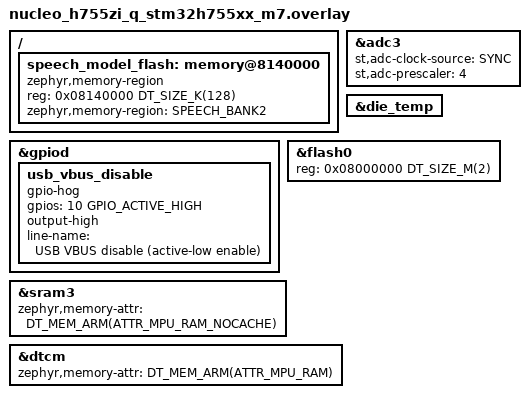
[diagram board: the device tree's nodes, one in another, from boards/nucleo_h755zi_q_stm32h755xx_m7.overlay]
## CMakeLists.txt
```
cmake_minimum_required(VERSION 3.20.0)

set(extra_conf_file "")
set(extra_dtc_overlay_file "")
set(board_compile_definitions "")

if(BOARD STREQUAL "nucleo_h755zi_q/stm32h755xx/m7")
  set(extra_conf_file "${CMAKE_CURRENT_SOURCE_DIR}/boards/nucleo_h755zi_q_stm32h755xx_m7.conf")
  set(extra_dtc_overlay_file "${CMAKE_CURRENT_SOURCE_DIR}/boards/nucleo_h755zi_q_stm32h755xx_m7.overlay")
  set(board_sources
    src/boot_optimizations.c
    src/board_io.c
    src/board_temperature_nucleo.c
    src/usb_host/stm32_hcd_adapter.c
    src/usb_host/usb_gpio_capture.c
    src/usb_host/usb_host_shell.c
    src/usb_host/usb_boot_mouse_class.c
    src/usb_host/usb_audio_capture.c
    src/usb_host/usb_audio_buffer.c
    src/usb_host/usb_audio_desc.c
    src/usb_host/usb_class_select.c
    third_party/stm32-mw-usb-host/Core/Src/usbh_core.c
    third_party/stm32-mw-usb-host/Core/Src/usbh_ctlreq.c
    third_party/stm32-mw-usb-host/Core/Src/usbh_ioreq.c
    third_party/stm32-mw-usb-host/Core/Src/usbh_pipes.c
  )
  set(board_include_dirs
    third_party/stm32-mw-usb-host/Core/Inc
  )
elseif(BOARD STREQUAL "native_sim/native/64")
  set(board_sources
    src/board_io_native_sim.c
    src/board_temperature_native_sim.c
    src/usb_host/usb_host_native_sim.c
  )
  set(board_compile_definitions APP_SIMULATED_HW)
elseif(BOARD STREQUAL "mps2/an500")
  set(extra_conf_file "${CMAKE_CURRENT_SOURCE_DIR}/boards/mps2_an500.conf")
  set(extra_dtc_overlay_file "${CMAKE_CURRENT_SOURCE_DIR}/boards/mps2_an500.overlay")
  set(board_sources
    src/board_io_native_sim.c
    src/board_temperature_native_sim.c
    src/usb_host/usb_host_native_sim.c
  )
  set(board_compile_definitions APP_SIMULATED_HW)
else()
  message(FATAL_ERROR "Unsupported BOARD target: ${BOARD}")
endif()

if(extra_conf_file)
  set(CONF_FILE "${CMAKE_CURRENT_SOURCE_DIR}/prj.conf;${extra_conf_file}" CACHE STRING "" FORCE)
endif()

if(extra_dtc_overlay_file)
  set(DTC_OVERLAY_FILE "${extra_dtc_overlay_file}" CACHE STRING "" FORCE)
endif()

set(SPEECH_TFLM_DIR "${CMAKE_CURRENT_SOURCE_DIR}/third_party/tflite-micro")
if(BOARD STREQUAL "nucleo_h755zi_q/stm32h755xx/m7")
  list(APPEND ZEPHYR_EXTRA_MODULES "${SPEECH_TFLM_DIR}")
endif()
find_package(Zephyr REQUIRED HINTS $ENV{ZEPHYR_BASE})
project(zephyr_hello_shell)

if(CONFIG_APP_USB_HOST_EVENT_WORKER)
  target_sources(app PRIVATE src/usb_host/usb_host_events.c)
endif()

if(CONFIG_APP_SPEECH_AI)
  include(cmake/speech_model.cmake)
  target_sources(app PRIVATE src/speech/speech_audio.c src/speech/speech_decision.c)
endif()
if(BOARD STREQUAL "nucleo_h755zi_q/stm32h755xx/m7")
  include(cmake/patch_stm32_hcd.cmake)
endif()

if(DEFINED ENV{SOURCE_DATE_EPOCH} AND
   NOT "$ENV{SOURCE_DATE_EPOCH}" MATCHES "^[0-9]+$")
  message(FATAL_ERROR "SOURCE_DATE_EPOCH must be a nonnegative integer")
endif()

string(TIMESTAMP APP_BUILD_TIMESTAMP "%Y-%m-%dT%H:%M:%SZ" UTC)
target_compile_definitions(app PRIVATE
  APP_BUILD_TIMESTAMP=\"${APP_BUILD_TIMESTAMP}\"
  ${board_compile_definitions}
)

target_sources(app PRIVATE
  src/main.c
  src/http_server.c
  src/web_assets.c
  src/mjpeg_multipart.c
  src/camera_frames.c
  src/camera_stream.c
  src/audio_wire.c
  src/audio_stream.c
  src/speech/speech_service.c
  src/speech/speech_attempt.c
  src/speech/speech_json.c
  src/usb_host/usb_boot_mouse_report.c
  ${board_sources}
)

target_include_directories(app PRIVATE
  src/usb_host
  src/speech
  ${board_include_dirs}
)

zephyr_linker_sources(SECTIONS sections-rom.ld)
zephyr_linker_section(NAME http_resource_desc_board_http_service
                      KVMA RAM_REGION GROUP RODATA_REGION)
```

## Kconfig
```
source "Kconfig.zephyr"

config APP_SPEECH_AI
	bool "On-board English keyword recognition"
	depends on APP_USB_HOST_HCD
	select CPP
	select TENSORFLOW_LITE_MICRO

config APP_HTTP_PORT
	int "Application HTTP server port"
	range 1 65535
	default 80
	help
	  TCP port used by the application dashboard and API.

config APP_USB_HOST_HCD
	bool "Enable STM32 USB host controller (HCD) support"
	default n
	select USE_STM32_HAL_HCD
	select USE_STM32_LL_USB
	select USE_STM32_HAL_PWR_EX
	help
	  Enables the STM32Cube HAL Host Controller Driver (HCD) module,
	  used by the STM32 USB Host Core bridge to drive OTG_FS in host
	  mode for USB device enumeration.

config APP_USB_HOST_EVENT_WORKER
	bool "Experimental FIFO-notification-driven USB host worker"
	depends on APP_USB_HOST_HCD
	default y
	select THREAD_RUNTIME_STATS
	help
	  Wake the USB host worker on queued HAL notifications and SOF ticks
	  instead of continuously busy-waiting in HOST_CLASS. Hardware IRQ
	  handling and microphone resubmission remain in interrupt context.
	  Disable for the original 50 us polling baseline.

config APP_USB_HOST_NO_IDLE_SLEEP
	bool "Diagnostic: skip CPU WFI/WFE while testing USB"
	depends on APP_USB_HOST_HCD
	select ARM_ON_ENTER_CPU_IDLE_HOOK
	default n
	help
	  Diagnostic comparison only. Keep the event worker blocking, but
	  prevent the idle thread from sleeping the CPU. This does not save
	  CPU power and must not be mistaken for a production fix.

config APP_USB_HOST_ULPI_SLEEP_CLOCK_FIX
	bool "Disable unused USB2 ULPI sleep clock for embedded FS PHY"
	depends on APP_USB_HOST_HCD
	default y
	help
	  Match Zephyr's STM32 USB device drivers: USB2's embedded FS PHY
	  needs the unused ULPI clock disabled in CPU sleep. Disable only
	  to reproduce the historical USB timing failure.

config APP_MPU_PROTECTION_TEST
	bool "Enable the test-only LED MPU cross-access probe"
	depends on USERSPACE
	default n
```

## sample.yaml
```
sample:
  description: External Hello World app with Zephyr serial shell and HTTP board I/O server
  name: zephyr hello shell
tests:
  app.zephyr_hello_shell:
    tags:
      - introduction
      - shell
    platform_allow:
      - nucleo_h755zi_q/stm32h755xx/m7
    harness: shell
    filter: CONFIG_SERIAL and dt_chosen_enabled("zephyr,shell-uart")
    harness_config:
      shell_commands:
        - command: "help"
          expected: "Available commands:"
        - command: "kernel version"
          expected: "Zephyr version .*"
        - command: "leds on green"
          expected: "green -> on"
        - command: "leds status green"
          expected: "green: on"
        - command: "leds off all"
          expected: "red -> off"
```

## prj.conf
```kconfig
CONFIG_MAIN_STACK_SIZE=3072
CONFIG_SYSTEM_WORKQUEUE_STACK_SIZE=1024

CONFIG_SERIAL=y
CONFIG_CONSOLE=y
CONFIG_UART_CONSOLE=y
CONFIG_GPIO=y
CONFIG_SHELL=y
CONFIG_SHELL_BACKEND_SERIAL=y
CONFIG_BOOT_BANNER=n
CONFIG_LOG=y
CONFIG_LOG_DEFAULT_LEVEL=2
CONFIG_LOG_CMDS=y
CONFIG_LOG_RUNTIME_FILTERING=y
CONFIG_LOG_RUNTIME_DEFAULT_LEVEL=2
CONFIG_LOG_BACKEND_UART=n
CONFIG_SHELL_LOG_BACKEND=y
CONFIG_SHELL_BACKEND_SERIAL_LOG_LEVEL_WRN=y
CONFIG_SHELL_THREAD_PRIORITY_OVERRIDE=y
CONFIG_SHELL_THREAD_PRIORITY=9
CONFIG_KERNEL_SHELL=y
CONFIG_THREAD_RUNTIME_STATS=y
CONFIG_JSON_LIBRARY=y

CONFIG_NETWORKING=y
CONFIG_NET_L2_ETHERNET=y
CONFIG_NET_IPV4=y
CONFIG_NET_TCP=y
CONFIG_NET_ARP=y
CONFIG_NET_CONFIG_SETTINGS=y
CONFIG_NET_CONFIG_NEED_IPV4=y
CONFIG_NET_CONFIG_MY_IPV4_ADDR="192.168.55.2"
CONFIG_NET_CONFIG_MY_IPV4_NETMASK="255.255.255.0"
CONFIG_NET_CONFIG_PEER_IPV4_ADDR="192.168.55.100"
# Don't block boot (main) waiting for PHY autonegotiation; the static
# address is still assigned immediately and the link comes up in background.
CONFIG_NET_CONFIG_INIT_TIMEOUT=0
CONFIG_NET_TCP_TIME_WAIT_DELAY=0
CONFIG_NET_SHELL=y
# The camera stream sends to one client at a time on a blocking socket.
# If a client disconnects uncleanly (no FIN/RST reaches the board, e.g.
# TCP window closes because the client just stops reading), a plain
# blocking send() can wait forever, wedging the single stream thread
# and holding onto its buffered/in-flight frame data indefinitely. That
# starves the shared network buffer pool the port-80 dashboard thread
# also needs. Enable per-socket send/receive timeouts so camera_stream.c
# can bound how long it waits on a stuck client and recover.
CONFIG_NET_CONTEXT_SNDTIMEO=y
CONFIG_NET_CONTEXT_RCVTIMEO=y
# Zephyr's global file-descriptor table (ZVFS_OPEN_MAX) defaults to only
# 4 slots, shared by every socket in the whole system. The dashboard
# alone already needs 4 (1 listener + CONFIG_HTTP_SERVER_MAX_CLIENTS=3),
# so the camera stream's 2 additional sockets (1 listener + 1 serving
# client) exhausted the pool and silently starved the dashboard of a
# free fd to accept new connections on. Size both the fd table and the
# poll() entry table generously for dashboard, camera and microphone:
# three listeners, three dashboard clients, camera client, mic client and
# one transient busy-response client, with teardown/headroom.
CONFIG_ZVFS_OPEN_MAX=20
CONFIG_ZVFS_POLL_MAX=12
CONFIG_NET_MAX_CONTEXTS=16
CONFIG_NET_MAX_CONN=16
CONFIG_SHELL_STACK_SIZE=3072
# TCP keeps unacknowledged data in a per-connection send queue built from
# TX DATA net_bufs, and each transmitted segment is a second copy from the
# same pool. The default pool (36 x 128 B) with its derived send window
# (pool/3 = 1536 B) deadlocks when camera (8081) and microphone (8082)
# stream together: both send queues pin ~25 buffers and the 11 left cannot
# hold one MSS segment, so neither connection can ever transmit again.
# Pin the per-connection window (2 x MSS) and size the pool for camera,
# microphone and dashboard windows plus several in-flight segment copies.
CONFIG_NET_TCP_MAX_SEND_WINDOW_SIZE=2920
CONFIG_NET_BUF_TX_COUNT=128
CONFIG_NET_PKT_TX_COUNT=32

CONFIG_HTTP_SERVER=y
CONFIG_HTTP_SERVER_NUM_SERVICES=1
CONFIG_HTTP_SERVER_STACK_SIZE=4096
CONFIG_HTTP_SERVER_MAX_CLIENTS=3
CONFIG_HTTP_SERVER_MAX_STREAMS=1
CONFIG_HTTP_SERVER_CLIENT_BUFFER_SIZE=256
CONFIG_HTTP_SERVER_CLIENT_INACTIVITY_TIMEOUT=1
CONFIG_HTTP_SERVER_MAX_URL_LENGTH=64
CONFIG_HTTP_SERVER_MAX_CONTENT_TYPE_LENGTH=64
```

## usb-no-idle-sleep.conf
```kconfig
CONFIG_APP_USB_HOST_NO_IDLE_SLEEP=y
CONFIG_APP_USB_HOST_ULPI_SLEEP_CLOCK_FIX=n
```

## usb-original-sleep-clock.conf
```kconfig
CONFIG_APP_USB_HOST_ULPI_SLEEP_CLOCK_FIX=n
```

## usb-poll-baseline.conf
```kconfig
CONFIG_APP_USB_HOST_EVENT_WORKER=n
CONFIG_THREAD_RUNTIME_STATS=y
CONFIG_APP_USB_HOST_ULPI_SLEEP_CLOCK_FIX=n
```

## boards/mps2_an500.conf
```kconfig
CONFIG_ETH_SMSC911X=y
CONFIG_ENTROPY_GENERATOR=y
CONFIG_TEST_RANDOM_GENERATOR=y
```

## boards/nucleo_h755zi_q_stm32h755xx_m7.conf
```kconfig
CONFIG_BOOT_BANNER=n
CONFIG_EARLY_CONSOLE=y
CONFIG_PRINTK=y
CONFIG_SPEED_OPTIMIZATIONS=y
# Without this, soc_early_init_hook's sys_cache_*_enable() are no-ops and the
# M7 runs with I/D cache off (speech inference was ~10x slower).
CONFIG_CACHE_MANAGEMENT=y
CONFIG_SOC_PREP_HOOK=y
# Keep SWD accessible when Zephyr's idle thread executes WFI.
CONFIG_STM32_ENABLE_DEBUG_SLEEP_STOP=y
# Configure fine-grained kernel timekeeping for zyclictest latency measurement.
CONFIG_TICKLESS_KERNEL=y
CONFIG_SYS_CLOCK_TICKS_PER_SEC=1000000
CONFIG_ZYCLICTEST_SHELL=y
# User-mode MPU permissions isolate the LED blink threads.
CONFIG_USERSPACE=y
# The application creates 17 threads; three permission bytes cover up to 24.
CONFIG_MAX_THREAD_BYTES=3
# Also protect stacks of supervisor-mode threads.
CONFIG_HW_STACK_PROTECTION=y
# The M7 image may extend into bank 2 sectors 0-1; sector 2 stores speech data.
CONFIG_FLASH_LOAD_SIZE=0x00140000
# MCU die temperature sensor (st,stm32-temp-cal on ADC3) for the dashboard.
CONFIG_ADC=y
CONFIG_SENSOR=y
CONFIG_SENSOR_SHELL=y
CONFIG_SENSOR_INFO=y
CONFIG_I2C=y
CONFIG_I2C_SHELL=y
CONFIG_SPI=y
CONFIG_SPI_SHELL=y
CONFIG_APP_USB_HOST_HCD=y
CONFIG_APP_SPEECH_AI=y
CONFIG_STD_CPP17=y
CONFIG_TENSORFLOW_LITE_MICRO_CMSIS_NN_KERNELS=y
# The CM4 is unused; M7 owns both flash banks and never starts the CM4.
CONFIG_STM32H7_BOOT_M4_AT_INIT=n

CONFIG_TRACING=y
CONFIG_TRACING_CTF=y
CONFIG_TRACING_SYNC=y
CONFIG_TRACING_BACKEND_RAM=y
CONFIG_TRACING_PACKET_MAX_SIZE=64
CONFIG_RAM_TRACING_BUFFER_SIZE=16384
```

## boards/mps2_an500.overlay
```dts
&eth0 {
	reg = <0xa0000000 0x100000>;
	status = "okay";
};
```

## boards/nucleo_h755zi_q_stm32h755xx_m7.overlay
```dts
#include <zephyr/dt-bindings/memory-attr/memory-attr-arm.h>

&gpiod {
	usb_vbus_disable {
		gpio-hog;
		gpios = <10 GPIO_ACTIVE_HIGH>;
		output-high;
		line-name = "USB VBUS disable (active-low enable)";
	};
};

/* MCU internal die temperature sensor (ADC3 channel 18, factory calibrated). */
&adc3 {
	st,adc-clock-source = "SYNC";
	st,adc-prescaler = <4>;
	status = "okay";
};

&die_temp {
	status = "okay";
};

/*
 * The CM4 is unused. M7 owns both 1 MiB flash banks; bank 2 sectors 0-1 extend
 * the image and sector 2 holds the read-only speech models. Keep BCM4=0 and
 * CONFIG_STM32H7_BOOT_M4_AT_INIT=n.
 */
&flash0 {
	reg = <0x08000000 DT_SIZE_M(2)>;
};

/ {
	speech_model_flash: memory@8140000 {
		compatible = "zephyr,memory-region";
		reg = <0x08140000 DT_SIZE_K(128)>;
		zephyr,memory-region = "SPEECH_BANK2";
	};
};

/* Ethernet DMA descriptors/buffers live here; keep them coherent with D-cache on. */
&sram3 {
	zephyr,memory-attr = <DT_MEM_ARM(ATTR_MPU_RAM_NOCACHE)>;
};

/* CPU-only speech arenas use DTCM; no peripheral DMA buffers belong here. */
&dtcm {
	zephyr,memory-attr = <DT_MEM_ARM(ATTR_MPU_RAM)>;
};
```

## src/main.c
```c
/*
 * SPDX-License-Identifier: Apache-2.0
 */

#include <errno.h>
#include <stdio.h>
#include <string.h>

#include <zephyr/kernel.h>
#include <zephyr/logging/log.h>
#include <zephyr/shell/shell.h>
#include <zephyr/shell/shell_string_conv.h>

#include "board_io.h"
#include "audio_stream.h"
#include "camera_stream.h"
#include "http_server.h"
#include "speech_service.h"

LOG_MODULE_REGISTER(app, LOG_LEVEL_DBG);

extern int board_usb_host_start(void);

#ifdef APP_SIMULATED_HW
extern void board_io_native_sim_button_set(bool pressed);

static int cmd_sim_button(const struct shell *shell, size_t argc, char **argv)
{
	if (argc != 2) {
		shell_error(shell, "usage: sim button <pressed|released>");
		return -EINVAL;
	}

	if (strcmp(argv[1], "pressed") == 0) {
		board_io_native_sim_button_set(true);
		shell_print(shell, "B1 (simulated) pressed");
	} else if (strcmp(argv[1], "released") == 0) {
		board_io_native_sim_button_set(false);
		shell_print(shell, "B1 (simulated) released");
	} else {
		shell_error(shell, "usage: sim button <pressed|released>");
		return -EINVAL;
	}

	return 0;
}

SHELL_STATIC_SUBCMD_SET_CREATE(sub_sim,
	SHELL_CMD_ARG(button, NULL, "Set the simulated user button state",
		      cmd_sim_button, 2, 0),
	SHELL_SUBCMD_SET_END
);

SHELL_CMD_REGISTER(sim, &sub_sim, "Simulation controls", NULL);
#endif

static int cmd_version(const struct shell *shell, size_t argc, char **argv)
{
	ARG_UNUSED(argc);
	ARG_UNUSED(argv);

	shell_print(shell, "zephyr-hello-shell");
	shell_print(shell, "Build time: %s", APP_BUILD_TIMESTAMP);
	return 0;
}

SHELL_CMD_REGISTER(version, NULL, "Show application build information", cmd_version);

static int cmd_cpu_usage(const struct shell *shell, size_t argc, char **argv)
{
	k_thread_runtime_stats_t before;
	k_thread_runtime_stats_t after;
	unsigned long interval_ms = 1000;
	uint64_t total;
	uint64_t busy;
	unsigned int busy_hundredths;
	unsigned int idle_hundredths;
	int err = 0;

	if (argc == 2) {
		interval_ms = shell_strtoul(argv[1], 10, &err);
		if (err != 0 || interval_ms == 0 || interval_ms > 60000) {
			shell_error(shell, "interval must be 1..60000 ms");
			return -EINVAL;
		}
	}

	err = k_thread_runtime_stats_cpu_get(0, &before);
	if (err != 0) {
		shell_error(shell, "CPU stats unavailable: %d", err);
		return err;
	}

	k_msleep((int32_t)interval_ms);

	err = k_thread_runtime_stats_cpu_get(0, &after);
	if (err != 0) {
		shell_error(shell, "CPU stats unavailable: %d", err);
		return err;
	}

	total = after.execution_cycles - before.execution_cycles;
	busy = after.total_cycles - before.total_cycles;
	if (total == 0 || busy > total) {
		shell_error(shell, "invalid CPU stats interval");
		return -EIO;
	}

	busy_hundredths = (unsigned int)(busy * 10000 / total);
	idle_hundredths = 10000 - busy_hundredths;
	shell_print(shell, "CPU busy: %u.%02u%%, idle: %u.%02u%% over %lu ms",
		    busy_hundredths / 100, busy_hundredths % 100,
		    idle_hundredths / 100, idle_hundredths % 100,
		    interval_ms);
	return 0;
}

SHELL_STATIC_SUBCMD_SET_CREATE(sub_cpu,
	SHELL_CMD_ARG(usage, NULL, "CPU busy/idle over [interval_ms] (default 1000)",
		      cmd_cpu_usage, 1, 1),
	SHELL_SUBCMD_SET_END
);

SHELL_CMD_REGISTER(cpu, &sub_cpu, "CPU utilization", NULL);

static int print_led_state(const struct shell *shell, enum board_led_id led_id, const char *separator)
{
	const struct board_led_info *led = board_led_info_get(led_id);
	bool is_on;
	int ret;

	if (led == NULL) {
		shell_error(shell, "unknown LED index %d", led_id);
		return -EINVAL;
	}

	ret = board_led_get(led_id, &is_on);
	if (ret != 0) {
		shell_error(shell, "%s state read failed: %d", led->color, ret);
		return ret;
	}

	shell_print(shell, "%s%s%s", led->color, separator, is_on ? "on" : "off");
	return 0;
}

static int apply_led_action(const struct shell *shell, enum board_led_id led_id, const char *action)
{
	const struct board_led_info *led = board_led_info_get(led_id);
	bool is_on;
	int ret;

	if (led == NULL) {
		shell_error(shell, "unknown LED index %d", led_id);
		return -EINVAL;
	}

	ret = board_led_apply_action(led_id, action, &is_on);
	if (ret != 0) {
		shell_error(shell, "%s %s failed: %d", action, led->color, ret);
		return ret;
	}

	shell_print(shell, "%s -> %s", led->color, is_on ? "on" : "off");
	return 0;
}

static int with_selected_leds(const struct shell *shell, const char *selection,
			      int (*callback)(const struct shell *shell, enum board_led_id led_id,
					      const char *arg),
			      const char *arg)
{
	int ret;

	ret = board_io_init();
	if (ret != 0) {
		shell_error(shell, "board I/O initialization failed: %d", ret);
		return ret;
	}

	if (strcmp(selection, "all") == 0) {
		for (enum board_led_id led_id = BOARD_LED_GREEN; led_id < BOARD_LED_COUNT; ++led_id) {
			ret = callback(shell, led_id, arg);
			if (ret != 0) {
				return ret;
			}
		}

		return 0;
	}

	enum board_led_id led_id;

	ret = board_led_find(selection, &led_id);
	if (ret != 0) {
		shell_error(shell, "unknown LED color '%s'; use green, yellow, red, or all",
			    selection);
		return ret;
	}

	return callback(shell, led_id, arg);
}

static int cmd_led_action(const struct shell *shell, size_t argc, char **argv)
{
	ARG_UNUSED(argc);

	return with_selected_leds(shell, argv[1], apply_led_action, argv[0]);
}

static int cmd_led_status(const struct shell *shell, size_t argc, char **argv)
{
	const char *selection = (argc > 1) ? argv[1] : "all";

	return with_selected_leds(shell, selection, print_led_state, ": ");
}

SHELL_STATIC_SUBCMD_SET_CREATE(sub_leds,
	SHELL_CMD_ARG(on, NULL, "Turn user LEDs on: leds on <green|yellow|red|all>",
		      cmd_led_action, 2, 0),
	SHELL_CMD_ARG(off, NULL, "Turn user LEDs off: leds off <green|yellow|red|all>",
		      cmd_led_action, 2, 0),
	SHELL_CMD_ARG(toggle, NULL, "Toggle user LEDs: leds toggle <green|yellow|red|all>",
		      cmd_led_action, 2, 0),
	SHELL_CMD_ARG(status, NULL, "Show LED state: leds status [green|yellow|red|all]",
		      cmd_led_status, 1, 1),
	SHELL_SUBCMD_SET_END
);

SHELL_CMD_REGISTER(leds, &sub_leds, "Control the user LEDs (LD1/LD2/LD3)", NULL);

int main(void)
{
	const char *http_host;
	int ret = board_io_init();

#if defined(CONFIG_ARCH_POSIX)
#if defined(CONFIG_NET_NATIVE_OFFLOADED_SOCKETS)
	http_host = "127.0.0.1";
#elif defined(CONFIG_ETH_NATIVE_TAP)
	http_host = CONFIG_NET_CONFIG_MY_IPV4_ADDR;
#else
#error "native_sim requires TAP or offloaded-socket networking"
#endif
#else
	http_host = CONFIG_NET_CONFIG_MY_IPV4_ADDR;
#endif

	LOG_INF("Hello World! %s", CONFIG_BOARD_TARGET);
	LOG_INF("Build time: %s", APP_BUILD_TIMESTAMP);

	if (ret != 0) {
		LOG_ERR("Board I/O initialization failed: %d", ret);
		return ret;
	}

	ret = board_blink_threads_start();
	if (ret != 0) {
		LOG_ERR("Blink thread startup failed: %d", ret);
		return ret;
	}

	LOG_INF("Blink threads started for yellow (%u ms) and red (%u ms)",
	       board_led_info_get(BOARD_LED_YELLOW)->blink_period_ms,
	       board_led_info_get(BOARD_LED_RED)->blink_period_ms);

	ret = board_http_server_start();
	if (ret != 0) {
		LOG_ERR("HTTP server startup failed: %d", ret);
		return ret;
	}

	LOG_INF("HTTP server listening on http://%s:%u/",
	       http_host, board_http_server_port());

	ret = board_usb_host_start();
	if (ret != 0) {
#ifdef APP_SIMULATED_HW
		if (ret == -ENOTSUP) {
			LOG_INF("USB host unsupported in simulation");
		} else {
			LOG_ERR("USB host startup failed: %d", ret);
		}
#else
		LOG_ERR("USB host startup failed: %d", ret);
#endif
		/* Non-fatal: continue running LEDs/HTTP even if USB host init failed. */
	}

	ret = speech_service_start();
	if (ret != 0 && ret != -ENOTSUP) {
		LOG_ERR("Speech recognition startup failed: %d", ret);
	}

	ret = camera_stream_start();
	if (ret != 0) {
		LOG_ERR("Camera stream startup failed: %d", ret);
		/* Non-fatal: continue running LEDs/HTTP even if the stream failed. */
	} else {
		LOG_INF("Camera stream listening on http://%s:%u/",
		       http_host, camera_stream_port());
	}

	ret = audio_stream_start();
	if (ret != 0) {
		LOG_ERR("Microphone stream startup failed: %d", ret);
	} else {
		LOG_INF("Microphone stream listening on http://%s:8082/", http_host);
	}

	return 0;
}
```

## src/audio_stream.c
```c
/* SPDX-License-Identifier: Apache-2.0 */
#include "audio_stream.h"

#include <errno.h>
#include <stdbool.h>
#include <stdint.h>
#include <stdio.h>
#include <string.h>

#include <zephyr/kernel.h>
#include <zephyr/logging/log.h>
#include <zephyr/net/socket.h>

#include "audio_wire.h"
#include "usb_host/usb_audio_capture.h"

LOG_MODULE_REGISTER(audio_stream, LOG_LEVEL_INF);

#ifndef AUDIO_PORT
#define AUDIO_PORT 8082
#endif
#define AUDIO_STACK_SIZE 4096
#define AUDIO_POLL_MS 4
#define AUDIO_REQUEST_MS 2000
#define AUDIO_STALL_MS 250
#define AUDIO_ERROR_MS 20
#define AUDIO_REQUEST_SIZE 8192
#define AUDIO_REQUEST_LINE_SIZE 256
#define AUDIO_RECV_SIZE 128
#define AUDIO_CHUNK_SIZE 2048

K_THREAD_STACK_DEFINE(audio_stack, AUDIO_STACK_SIZE);
static struct k_thread audio_thread;
static bool audio_started;

struct audio_client {
	int fd;
	char request_line[AUDIO_REQUEST_LINE_SIZE];
	size_t request_line_len;
	size_t request_bytes;
	uint8_t header_match;
	bool request_line_done;
	uint8_t data[AUDIO_CHUNK_SIZE];
	size_t length;
	size_t offset;
	uint32_t session;
	int64_t deadline;
	bool streaming;
};

/*
 * Error replies are small; write them fully, but within a short bound so a
 * peer that does not read cannot stall the active stream.
 */
static void send_error(int fd, const char *status, const char *reason)
{
	char response[256];
	int64_t deadline = k_uptime_get() + AUDIO_ERROR_MS;
	size_t sent = 0;
	int n = snprintk(response, sizeof(response),
			 "HTTP/1.1 %s\r\nContent-Type: text/plain\r\n"
			 "Cache-Control: no-store\r\nAccess-Control-Allow-Origin: *\r\n"
			 "Connection: close\r\nContent-Length: %u\r\n\r\n%s",
			 status, (unsigned int)strlen(reason), reason);

	if (n <= 0 || (size_t)n >= sizeof(response)) {
		return;
	}
	while (sent < (size_t)n) {
		ssize_t r = zsock_send(fd, response + sent, (size_t)n - sent,
				       ZSOCK_MSG_DONTWAIT);
		struct zsock_pollfd pfd = {.fd = fd, .events = ZSOCK_POLLOUT};
		int64_t left;

		if (r > 0) {
			sent += (size_t)r;
			continue;
		}
		if (r == 0 || (errno != EAGAIN && errno != EWOULDBLOCK)) {
			return;
		}
		left = deadline - k_uptime_get();
		if (left <= 0 || zsock_poll(&pfd, 1, (int)left) <= 0) {
			return;
		}
	}
}

static void close_client(struct audio_client *client)
{
	if (client->fd >= 0) {
		zsock_close(client->fd);
	}
	client->fd = -1;
	client->streaming = false;
	client->length = 0;
	client->offset = 0;
}

static bool valid_request_line(const char *line, size_t length)
{
	const char *target;
	const char *space;
	size_t target_len;
	size_t version_len;

	if (length < 14U || memcmp(line, "GET ", 4U) != 0) {
		return false;
	}
	target = line + 4;
	space = memchr(target, ' ', length - 4U);
	if (space == NULL) {
		return false;
	}
	target_len = (size_t)(space - target);
	if (target_len == 1U) {
		if (target[0] != '/') {
			return false;
		}
	} else if (target_len < 2U || target[0] != '/' || target[1] != '?') {
		return false;
	}
	for (size_t i = 0; i < target_len; ++i) {
		if ((unsigned char)target[i] <= 0x20U || target[i] == 0x7f) {
			return false;
		}
	}
	version_len = length - (size_t)(space + 1 - line);
	return (version_len == 8U && memcmp(space + 1, "HTTP/1.0", 8U) == 0) ||
	       (version_len == 8U && memcmp(space + 1, "HTTP/1.1", 8U) == 0);
}

static void accept_request(struct audio_client *client)
{
	struct usb_audio_snapshot snapshot;
	char header[192];
	uint8_t wire[16];
	int n;

	usb_audio_snapshot_get(&snapshot);
	if (!snapshot.connected || !snapshot.ready || snapshot.session == 0U ||
	    snapshot.sample_rate_hz == 0U || snapshot.channels == 0U ||
	    snapshot.bits_per_sample == 0U || snapshot.bits_per_sample % 8U != 0U ||
	    snapshot.channels * (snapshot.bits_per_sample / 8U) > AUDIO_CHUNK_SIZE) {
		send_error(client->fd, "503 Service Unavailable",
			   snapshot.reason != NULL ? snapshot.reason : "microphone unavailable");
		close_client(client);
		return;
	}

	if (audio_wire_header(wire, snapshot.sample_rate_hz, snapshot.channels,
			      snapshot.bits_per_sample, snapshot.session) != 0) {
		close_client(client);
		return;
	}

	/* Start live, not with up to 250 ms of pre-connection ring contents. */
	for (size_t i = 0; i < 48; ++i) {
		if (usb_audio_read(snapshot.session, client->data,
				   sizeof(client->data)) == 0U) {
			break;
		}
	}

	n = snprintk(header, sizeof(header),
		     "HTTP/1.1 200 OK\r\nContent-Type: application/octet-stream\r\n"
		     "Cache-Control: no-store\r\nAccess-Control-Allow-Origin: *\r\n"
		     "Connection: close\r\n\r\n");
	if (n <= 0 || (size_t)n + sizeof(wire) > sizeof(client->data)) {
		close_client(client);
		return;
	}
	memcpy(client->data, header, (size_t)n);
	memcpy(client->data + n, wire, sizeof(wire));
	client->length = (size_t)n + sizeof(wire);
	client->offset = 0;
	client->session = snapshot.session;
	client->streaming = true;
	client->deadline = k_uptime_get() + AUDIO_STALL_MS;
}

static void reject_bad_request(struct audio_client *client)
{
	send_error(client->fd, "400 Bad Request", "expected GET /");
	close_client(client);
}

static void receive_request(struct audio_client *client)
{
	char incoming[AUDIO_RECV_SIZE];
	ssize_t n = zsock_recv(client->fd, incoming, sizeof(incoming), ZSOCK_MSG_DONTWAIT);

	if (n <= 0) {
		if (n == 0 || (errno != EAGAIN && errno != EWOULDBLOCK)) {
			close_client(client);
		}
		return;
	}

	for (ssize_t i = 0; i < n; ++i) {
		char byte = incoming[i];

		if (++client->request_bytes > AUDIO_REQUEST_SIZE) {
			send_error(client->fd, "400 Bad Request", "request too large");
			close_client(client);
			return;
		}
		if (!client->request_line_done) {
			if (client->request_line_len >= sizeof(client->request_line) - 1U) {
				reject_bad_request(client);
				return;
			}
			client->request_line[client->request_line_len++] = byte;
			if (byte == '\n' && client->request_line_len >= 2U &&
			    client->request_line[client->request_line_len - 2U] == '\r') {
				client->request_line_len -= 2U;
				client->request_line[client->request_line_len] = '\0';
				client->request_line_done = true;
				if (!valid_request_line(client->request_line, client->request_line_len)) {
					reject_bad_request(client);
					return;
				}
			} else if (byte == '\n') {
				reject_bad_request(client);
				return;
			}
		}

		/* Four-byte CRLFCRLF matcher, including sequences split between recv calls. */
		switch (client->header_match) {
		case 0:
			client->header_match = byte == '\r' ? 1U : 0U;
			break;
		case 1:
			client->header_match = byte == '\n' ? 2U : (byte == '\r' ? 1U : 0U);
			break;
		case 2:
			client->header_match = byte == '\r' ? 3U : 0U;
			break;
		case 3:
			if (byte == '\n') {
				if (!client->request_line_done) {
					reject_bad_request(client);
				} else {
					accept_request(client);
				}
				return;
			}
			client->header_match = byte == '\r' ? 1U : 0U;
			break;
		default:
			client->header_match = 0U;
			break;
		}
	}
}

static void send_audio(struct audio_client *client)
{
	struct usb_audio_snapshot snapshot;
	ssize_t n;

	usb_audio_snapshot_get(&snapshot);
	if (!snapshot.ready || !snapshot.connected || snapshot.session != client->session) {
		close_client(client);
		return;
	}

	if (client->offset == client->length) {
		client->length = usb_audio_read(client->session, client->data,
						sizeof(client->data));
		client->offset = 0;
		if (client->length == 0U) {
			return;
		}
		client->deadline = k_uptime_get() + AUDIO_STALL_MS;
	}

	n = zsock_send(client->fd, client->data + client->offset,
		       client->length - client->offset, ZSOCK_MSG_DONTWAIT);
	if (n > 0) {
		client->offset += (size_t)n;
		client->deadline = k_uptime_get() + AUDIO_STALL_MS;
	} else if (n == 0 || (errno != EAGAIN && errno != EWOULDBLOCK)) {
		close_client(client);
	}
}

static void audio_thread_entry(void *p1, void *p2, void *p3)
{
	struct sockaddr_in addr = {
		.sin_family = AF_INET,
		.sin_port = htons(AUDIO_PORT),
		.sin_addr.s_addr = htonl(INADDR_ANY),
	};
	/* Static: the 2.4 KB client buffers would nearly fill the thread stack. */
	static struct audio_client client = {.fd = -1};
	struct zsock_pollfd fds[2];
	int server;

	ARG_UNUSED(p1);
	ARG_UNUSED(p2);
	ARG_UNUSED(p3);

	server = zsock_socket(AF_INET, SOCK_STREAM, IPPROTO_TCP);
	if (server < 0) {
		LOG_ERR("socket failed: %d", errno);
		return;
	}
	if (zsock_bind(server, (struct sockaddr *)&addr, sizeof(addr)) < 0 ||
	    zsock_listen(server, 2) < 0) {
		LOG_ERR("bind/listen failed: %d", errno);
		zsock_close(server);
		return;
	}

	LOG_INF("Microphone stream listening on port %d", AUDIO_PORT);
	while (true) {
		fds[0] = (struct zsock_pollfd){.fd = server, .events = ZSOCK_POLLIN};
		fds[1] = (struct zsock_pollfd){
			.fd = client.fd,
			.events = client.streaming && client.offset < client.length ?
					  (ZSOCK_POLLOUT | ZSOCK_POLLIN) : ZSOCK_POLLIN,
		};
		bool client_polled = client.fd >= 0;
		int count = zsock_poll(fds, client_polled ? 2 : 1, AUDIO_POLL_MS);

		if (count < 0) {
			k_msleep(AUDIO_POLL_MS);
			continue;
		}
		if (fds[0].revents & ZSOCK_POLLIN) {
			int fd = zsock_accept(server, NULL, NULL);

			if (fd >= 0) {
				struct zsock_timeval timeout = { .tv_sec = 1, .tv_usec = 0 };

				(void)zsock_setsockopt(fd, SOL_SOCKET, SO_SNDTIMEO,
						       &timeout, sizeof(timeout));
				(void)zsock_setsockopt(fd, SOL_SOCKET, SO_RCVTIMEO,
						       &timeout, sizeof(timeout));
				if (client.fd >= 0) {
					send_error(fd, "409 Conflict", "microphone stream busy");
					zsock_close(fd);
				} else {
					client.fd = fd;
					client.request_line_len = 0;
					client.request_bytes = 0;
					client.header_match = 0;
					client.request_line_done = false;
					client.length = 0;
					client.streaming = false;
					client.deadline = k_uptime_get() + AUDIO_REQUEST_MS;
				}
			}
		}
		/*
		 * fds[1].revents is only valid if the client was polled; a client
		 * accepted just now is handled on the next (immediate) poll.
		 */
		if (client.fd < 0 || !client_polled) {
			continue;
		}
		if (k_uptime_get() >= client.deadline ||
		    (fds[1].revents & (ZSOCK_POLLERR | ZSOCK_POLLHUP | ZSOCK_POLLNVAL))) {
			close_client(&client);
		} else if (client.streaming) {
			/* Detect FIN without waiting for a pending PCM write. */
			if (fds[1].revents & ZSOCK_POLLIN) {
				char byte;
				ssize_t n = zsock_recv(client.fd, &byte, 1,
						       ZSOCK_MSG_PEEK | ZSOCK_MSG_DONTWAIT);

				if (n >= 0 || (errno != EAGAIN && errno != EWOULDBLOCK)) {
					close_client(&client);
				}
			}
			if (client.fd >= 0) {
				send_audio(&client);
			}
		} else if (fds[1].revents & ZSOCK_POLLIN) {
			receive_request(&client);
		}
	}
}

int audio_stream_start(void)
{
	if (audio_started) {
		return 0;
	}

	k_tid_t tid = k_thread_create(&audio_thread, audio_stack,
				      K_THREAD_STACK_SIZEOF(audio_stack),
				      audio_thread_entry, NULL, NULL, NULL, 7, 0, K_NO_WAIT);

	k_thread_name_set(tid, "audio_stream");
	audio_started = true;
	return 0;
}
```

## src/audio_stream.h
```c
/* SPDX-License-Identifier: Apache-2.0 */
#ifndef AUDIO_STREAM_H_
#define AUDIO_STREAM_H_

int audio_stream_start(void);

#endif /* AUDIO_STREAM_H_ */
```

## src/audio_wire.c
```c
/* SPDX-License-Identifier: Apache-2.0 */
#include "audio_wire.h"

#include <errno.h>
#include <stddef.h>

int audio_wire_header(uint8_t out[16], uint32_t rate, uint16_t channels,
		      uint16_t bits, uint32_t session)
{
	if (out == NULL) {
		return -EINVAL;
	}

	out[0] = 'M';
	out[1] = 'I';
	out[2] = 'C';
	out[3] = '1';
	out[4] = (uint8_t)rate;
	out[5] = (uint8_t)(rate >> 8);
	out[6] = (uint8_t)(rate >> 16);
	out[7] = (uint8_t)(rate >> 24);
	out[8] = (uint8_t)channels;
	out[9] = (uint8_t)(channels >> 8);
	out[10] = (uint8_t)bits;
	out[11] = (uint8_t)(bits >> 8);
	out[12] = (uint8_t)session;
	out[13] = (uint8_t)(session >> 8);
	out[14] = (uint8_t)(session >> 16);
	out[15] = (uint8_t)(session >> 24);
	return 0;
}
```

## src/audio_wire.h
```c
/* SPDX-License-Identifier: Apache-2.0 */
#ifndef AUDIO_WIRE_H_
#define AUDIO_WIRE_H_

#include <stdint.h>

int audio_wire_header(uint8_t out[16], uint32_t rate, uint16_t channels,
		      uint16_t bits, uint32_t session);

#endif /* AUDIO_WIRE_H_ */
```

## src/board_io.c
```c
/*
 * SPDX-License-Identifier: Apache-2.0
 */

#include "board_io.h"

#include <errno.h>
#include <string.h>

#include <zephyr/kernel.h>
#include <zephyr/app_memory/mem_domain.h>
#include <zephyr/devicetree.h>
#include <zephyr/drivers/gpio.h>
#include <zephyr/shell/shell.h>
#include <zephyr/sys/libc-hooks.h>
#include <zephyr/sys/printk.h>
#include <zephyr/sys/util.h>

#define LED_USER_REGION_SIZE 64U

struct board_led {
	enum board_led_id id;
	struct board_led_info info;
	struct gpio_dt_spec gpio;
};

struct board_led_region {
	struct board_led led;
	uint8_t padding[LED_USER_REGION_SIZE - sizeof(struct board_led)];
} __aligned(LED_USER_REGION_SIZE);

BUILD_ASSERT(sizeof(struct board_led) <= LED_USER_REGION_SIZE);
BUILD_ASSERT(sizeof(struct board_led_region) == LED_USER_REGION_SIZE);

static struct board_led green_led = {
	.id = BOARD_LED_GREEN,
	.info =
		{
			.color = "green",
			.label = "LD1",
			.blinking = false,
			.blink_period_ms = 0,
		},
	.gpio = GPIO_DT_SPEC_GET(DT_NODELABEL(green_led), gpios),
};

static struct board_led_region yellow_led_region = {
	.led =
		{
			.id = BOARD_LED_YELLOW,
			.info =
				{
					.color = "yellow",
					.label = "LD2",
					.blinking = true,
					.blink_period_ms = 400U,
				},
			.gpio = GPIO_DT_SPEC_GET(DT_NODELABEL(yellow_led), gpios),
		},
};

static struct board_led_region red_led_region = {
	.led =
		{
			.id = BOARD_LED_RED,
			.info =
				{
					.color = "red",
					.label = "LD3",
					.blinking = true,
					.blink_period_ms = 700U,
				},
			.gpio = GPIO_DT_SPEC_GET(DT_NODELABEL(red_led), gpios),
		},
};

K_MEM_PARTITION_DEFINE(yellow_led_partition, &yellow_led_region, sizeof(yellow_led_region),
		       K_MEM_PARTITION_P_RW_U_RW);
K_MEM_PARTITION_DEFINE(red_led_partition, &red_led_region, sizeof(red_led_region),
		       K_MEM_PARTITION_P_RW_U_RW);

static struct k_mem_domain yellow_led_domain;
static struct k_mem_domain red_led_domain;

static struct k_mem_partition *yellow_led_partitions[] = {
#if Z_LIBC_PARTITION_EXISTS
	&z_libc_partition,
#endif
	&yellow_led_partition,
};
static struct k_mem_partition *red_led_partitions[] = {
#if Z_LIBC_PARTITION_EXISTS
	&z_libc_partition,
#endif
	&red_led_partition,
};

static struct board_led *const board_leds[] = {
	&green_led,
	&yellow_led_region.led,
	&red_led_region.led,
};

static const struct gpio_dt_spec user_button = GPIO_DT_SPEC_GET(DT_NODELABEL(user_button), gpios);

static bool board_io_initialized;
static int board_io_init_status;
static bool blink_threads_started;
static int blink_threads_start_error;

static K_MUTEX_DEFINE(board_io_lock);

#define LED_BLINK_THREAD_STACK_SIZE 512
#define LED_BLINK_THREAD_PRIORITY 7

K_THREAD_STACK_DEFINE(yellow_led_blink_stack, LED_BLINK_THREAD_STACK_SIZE);
K_THREAD_STACK_DEFINE(red_led_blink_stack, LED_BLINK_THREAD_STACK_SIZE);

static struct k_thread yellow_led_blink_thread;
static struct k_thread red_led_blink_thread;

#if defined(CONFIG_APP_MPU_PROTECTION_TEST)
#define MPU_PROBE_THREAD_STACK_SIZE 256
K_THREAD_STACK_DEFINE(mpu_probe_stack, MPU_PROBE_THREAD_STACK_SIZE);
static struct k_thread mpu_probe_thread_data;

static void mpu_probe_thread(void *arg1, void *arg2, void *arg3)
{
	volatile uint8_t *address = arg1;
	int write_access = POINTER_TO_INT(arg2);

	if (write_access != 0) {
		*address = 0xA5U;
	} else {
		volatile uint8_t value = *address;
		ARG_UNUSED(value);
	}
	ARG_UNUSED(arg3);
}

static int cmd_mpu_probe(const struct shell *shell, size_t argc, char **argv)
{
	volatile uint8_t *address;
	bool write_access;
	k_tid_t tid;
	int ret;

	if (argc != 2) {
		shell_error(shell,
			    "usage: mpu_probe state-read|state-write|stack-read|stack-write");
		return -EINVAL;
	}

	if ((strcmp(argv[1], "state-read") == 0) || (strcmp(argv[1], "state-write") == 0)) {
		address = (volatile uint8_t *)&red_led_region.led.info.blink_period_ms;
	} else if ((strcmp(argv[1], "stack-read") == 0) ||
		   (strcmp(argv[1], "stack-write") == 0)) {
		address = (volatile uint8_t *)K_THREAD_STACK_BUFFER(red_led_blink_stack);
	} else {
		shell_error(shell, "unknown probe mode");
		return -EINVAL;
	}

	write_access = (strcmp(argv[1], "state-write") == 0) ||
		       (strcmp(argv[1], "stack-write") == 0);

	tid = k_thread_create(&mpu_probe_thread_data, mpu_probe_stack,
			      K_THREAD_STACK_SIZEOF(mpu_probe_stack), mpu_probe_thread,
			      (void *)address, INT_TO_POINTER(write_access), NULL,
			      LED_BLINK_THREAD_PRIORITY, K_USER, K_FOREVER);
	ret = k_mem_domain_add_thread(&yellow_led_domain, tid);
	if (ret != 0) {
		k_thread_abort(tid);
		shell_error(shell, "could not assign probe memory domain: %d", ret);
		return ret;
	}

	k_thread_name_set(tid, "mpu_probe");
	shell_print(shell, "started %s; expected MPU fault", argv[1]);
	k_thread_start(tid);
	return 0;
}

SHELL_CMD_REGISTER(mpu_probe, NULL, "Test LED MPU isolation", cmd_mpu_probe);
#endif

struct board_led_error {
	enum board_led_id led_id;
	int error;
};

K_MSGQ_DEFINE(board_io_error_queue, sizeof(struct board_led_error), 4, 4);
K_THREAD_STACK_DEFINE(board_io_error_stack, 1024);
static struct k_thread board_io_error_thread;

static void board_io_error_thread_entry(void *arg1, void *arg2, void *arg3)
{
	struct board_led_error error;
	int ret;

	ARG_UNUSED(arg1);
	ARG_UNUSED(arg2);
	ARG_UNUSED(arg3);

	while (true) {
		ret = k_msgq_get(&board_io_error_queue, &error, K_FOREVER);
		if (ret != 0) {
			printk("LED error queue receive failed: %d\n", ret);
			continue;
		}

		if (error.led_id < BOARD_LED_GREEN || error.led_id >= BOARD_LED_COUNT) {
			printk("LED error queue received invalid LED ID: %d\n", error.led_id);
			continue;
		}

		printk("%s LED toggle failed: %d\n", board_leds[error.led_id]->info.color, error.error);
	}
}

static struct board_led *board_led_from_id(enum board_led_id led_id)
{
	if (led_id < BOARD_LED_GREEN || led_id >= BOARD_LED_COUNT) {
		return NULL;
	}

	return board_leds[led_id];
}

static void led_blink_thread(void *arg1, void *arg2, void *arg3)
{
	struct board_led *led = arg1;
	struct board_led_error error;
	const int blink_period_ms = POINTER_TO_INT(arg2);
	int ret;

	ARG_UNUSED(arg3);

	while (true) {
		k_mutex_lock(&board_io_lock, K_FOREVER);
		ret = gpio_pin_toggle_dt(&led->gpio);
		k_mutex_unlock(&board_io_lock);

		if (ret != 0) {
			error.led_id = led->id;
			error.error = ret;
			ret = k_msgq_put(&board_io_error_queue, &error, K_FOREVER);
			if (ret != 0) {
				k_oops();
			}
		}

		k_msleep(blink_period_ms);
	}
}

int board_io_init(void)
{
	int ret;

	if (board_io_initialized) {
		return board_io_init_status;
	}

	for (size_t i = 0; i < ARRAY_SIZE(board_leds); ++i) {
		if (!gpio_is_ready_dt(&board_leds[i]->gpio)) {
			board_io_initialized = true;
			board_io_init_status = -ENODEV;
			return board_io_init_status;
		}
	}

	if (!gpio_is_ready_dt(&user_button)) {
		board_io_initialized = true;
		board_io_init_status = -ENODEV;
		return board_io_init_status;
	}

	for (size_t i = 0; i < ARRAY_SIZE(board_leds); ++i) {
		ret = gpio_pin_configure_dt(&board_leds[i]->gpio, GPIO_OUTPUT_INACTIVE);
		if (ret != 0) {
			board_io_initialized = true;
			board_io_init_status = ret;
			return ret;
		}
	}

	ret = gpio_pin_configure_dt(&user_button, GPIO_INPUT);
	if (ret != 0) {
		board_io_initialized = true;
		board_io_init_status = ret;
		return ret;
	}

	board_io_initialized = true;
	board_io_init_status = 0;
	return 0;
}

int board_blink_threads_start(void)
{
	int ret;

	ret = board_io_init();
	if (ret != 0) {
		return ret;
	}

	if (blink_threads_started) {
		return 0;
	}

	if (blink_threads_start_error != 0) {
		return blink_threads_start_error;
	}

	ret = k_mem_domain_init(&yellow_led_domain, ARRAY_SIZE(yellow_led_partitions),
				yellow_led_partitions);
	if (ret != 0) {
		blink_threads_start_error = ret;
		return ret;
	}

	ret = k_mem_domain_init(&red_led_domain, ARRAY_SIZE(red_led_partitions), red_led_partitions);
	if (ret != 0) {
		blink_threads_start_error = ret;
		return ret;
	}

	k_tid_t yellow_tid = k_thread_create(&yellow_led_blink_thread, yellow_led_blink_stack,
					     K_THREAD_STACK_SIZEOF(yellow_led_blink_stack),
					     led_blink_thread, &yellow_led_region.led,
					     INT_TO_POINTER(
						     yellow_led_region.led.info.blink_period_ms),
					     NULL, LED_BLINK_THREAD_PRIORITY, K_USER, K_FOREVER);
	k_tid_t red_tid = k_thread_create(&red_led_blink_thread, red_led_blink_stack,
					  K_THREAD_STACK_SIZEOF(red_led_blink_stack),
					  led_blink_thread, &red_led_region.led,
					  INT_TO_POINTER(red_led_region.led.info.blink_period_ms),
					  NULL, LED_BLINK_THREAD_PRIORITY, K_USER, K_FOREVER);

	ret = k_mem_domain_add_thread(&yellow_led_domain, yellow_tid);
	if (ret == 0) {
		ret = k_mem_domain_add_thread(&red_led_domain, red_tid);
	}
	if (ret != 0) {
		k_thread_abort(yellow_tid);
		k_thread_abort(red_tid);
		blink_threads_start_error = ret;
		return ret;
	}

	k_object_access_grant(&board_io_lock, yellow_tid);
	k_object_access_grant(yellow_led_region.led.gpio.port, yellow_tid);
	k_object_access_grant(&board_io_error_queue, yellow_tid);
	k_object_access_grant(&board_io_lock, red_tid);
	k_object_access_grant(red_led_region.led.gpio.port, red_tid);
	k_object_access_grant(&board_io_error_queue, red_tid);

	/* Created only after all fallible setup, so no failure path can leave it running. */
	k_tid_t logger_tid =
		k_thread_create(&board_io_error_thread, board_io_error_stack,
				K_THREAD_STACK_SIZEOF(board_io_error_stack),
				board_io_error_thread_entry, NULL, NULL, NULL,
				LED_BLINK_THREAD_PRIORITY + 1, 0, K_NO_WAIT);

	k_thread_name_set(logger_tid, "board_io_error");
	k_thread_name_set(yellow_tid, "yellow_led_blink");
	k_thread_name_set(red_tid, "red_led_blink");
	k_thread_start(yellow_tid);
	k_thread_start(red_tid);
	blink_threads_started = true;

	return 0;
}

size_t board_led_count(void)
{
	return ARRAY_SIZE(board_leds);
}

void board_blink_threads_suspend(void)
{
	if (blink_threads_started) {
		k_thread_suspend(&yellow_led_blink_thread);
		k_thread_suspend(&red_led_blink_thread);
	}
}

void board_blink_threads_resume(void)
{
	if (blink_threads_started) {
		k_thread_resume(&yellow_led_blink_thread);
		k_thread_resume(&red_led_blink_thread);
	}
}

const struct board_led_info *board_led_info_get(enum board_led_id led_id)
{
	struct board_led *led = board_led_from_id(led_id);

	return led == NULL ? NULL : &led->info;
}

int board_led_find(const char *color, enum board_led_id *led_id)
{
	if (color == NULL || led_id == NULL) {
		return -EINVAL;
	}

	for (size_t i = 0; i < ARRAY_SIZE(board_leds); ++i) {
		if (strcmp(board_leds[i]->info.color, color) == 0) {
			*led_id = (enum board_led_id)i;
			return 0;
		}
	}

	return -ENOENT;
}

int board_led_get(enum board_led_id led_id, bool *is_on)
{
	struct board_led *led = board_led_from_id(led_id);
	int value;

	if (led == NULL || is_on == NULL) {
		return -EINVAL;
	}

	k_mutex_lock(&board_io_lock, K_FOREVER);
	value = gpio_pin_get_dt(&led->gpio);
	k_mutex_unlock(&board_io_lock);

	if (value < 0) {
		return value;
	}

	*is_on = (value != 0);
	return 0;
}

int board_led_apply_action(enum board_led_id led_id, const char *action, bool *is_on)
{
	struct board_led *led = board_led_from_id(led_id);
	int ret;
	int value;

	if (led == NULL || action == NULL) {
		return -EINVAL;
	}

	k_mutex_lock(&board_io_lock, K_FOREVER);

	if (strcmp(action, "on") == 0) {
		ret = gpio_pin_set_dt(&led->gpio, 1);
	} else if (strcmp(action, "off") == 0) {
		ret = gpio_pin_set_dt(&led->gpio, 0);
	} else if (strcmp(action, "toggle") == 0) {
		ret = gpio_pin_toggle_dt(&led->gpio);
	} else {
		k_mutex_unlock(&board_io_lock);
		return -EINVAL;
	}

	if (ret == 0 && is_on != NULL) {
		value = gpio_pin_get_dt(&led->gpio);
		if (value < 0) {
			ret = value;
		} else {
			*is_on = (value != 0);
		}
	}

	k_mutex_unlock(&board_io_lock);
	return ret;
}

const char *board_button_label(void)
{
	return "B1";
}

int board_button_get(bool *pressed)
{
	int value;

	if (pressed == NULL) {
		return -EINVAL;
	}

	k_mutex_lock(&board_io_lock, K_FOREVER);
	value = gpio_pin_get_dt(&user_button);
	k_mutex_unlock(&board_io_lock);

	if (value < 0) {
		return value;
	}

	*pressed = (value != 0);
	return 0;
}
```

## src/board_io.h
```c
/*
 * SPDX-License-Identifier: Apache-2.0
 */

#ifndef ZEPHYR_HELLO_SHELL_BOARD_IO_H_
#define ZEPHYR_HELLO_SHELL_BOARD_IO_H_

#include <stdbool.h>
#include <stddef.h>
#include <stdint.h>

enum board_led_id {
	BOARD_LED_GREEN = 0,
	BOARD_LED_YELLOW,
	BOARD_LED_RED,
	BOARD_LED_COUNT,
};

struct board_led_info {
	const char *color;
	const char *label;
	bool blinking;
	uint32_t blink_period_ms;
};

int board_io_init(void);
int board_blink_threads_start(void);
void board_blink_threads_suspend(void);
void board_blink_threads_resume(void);

size_t board_led_count(void);
const struct board_led_info *board_led_info_get(enum board_led_id led_id);
int board_led_find(const char *color, enum board_led_id *led_id);
int board_led_get(enum board_led_id led_id, bool *is_on);
int board_led_apply_action(enum board_led_id led_id, const char *action, bool *is_on);

const char *board_button_label(void);
int board_button_get(bool *pressed);

#endif /* ZEPHYR_HELLO_SHELL_BOARD_IO_H_ */
```

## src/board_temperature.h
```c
/*
 * SPDX-License-Identifier: Apache-2.0
 */

#ifndef ZEPHYR_HELLO_SHELL_BOARD_TEMPERATURE_H_
#define ZEPHYR_HELLO_SHELL_BOARD_TEMPERATURE_H_

#include <stdint.h>

struct board_temperature {
	int32_t milli_celsius;
	const char *source;
};

int board_temperature_get(struct board_temperature *temperature);

#endif /* ZEPHYR_HELLO_SHELL_BOARD_TEMPERATURE_H_ */
```

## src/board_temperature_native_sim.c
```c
/*
 * SPDX-License-Identifier: Apache-2.0
 */

#include "board_temperature.h"

#include <errno.h>
#include <stddef.h>

int board_temperature_get(struct board_temperature *temperature)
{
	if (temperature == NULL) {
		return -EINVAL;
	}

	temperature->milli_celsius = 25000;
	temperature->source = "simulated";
	return 0;
}
```

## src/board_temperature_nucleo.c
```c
/*
 * SPDX-License-Identifier: Apache-2.0
 */

#include "board_temperature.h"

#include <errno.h>
#include <stddef.h>

#include <zephyr/device.h>
#include <zephyr/drivers/sensor.h>
#include <zephyr/kernel.h>

#define DIE_TEMP_NODE DT_NODELABEL(die_temp)
#define DIE_TEMP_REFRESH_MS 1000

/* The dashboard polls /api/v1/io every 100 ms; sample the ADC at most once per second. */
int board_temperature_get(struct board_temperature *temperature)
{
	if (temperature == NULL) {
		return -EINVAL;
	}

#if DT_NODE_HAS_STATUS_OKAY(DIE_TEMP_NODE)
	static const struct device *const dev = DEVICE_DT_GET(DIE_TEMP_NODE);
	static K_MUTEX_DEFINE(lock);
	static int64_t last_ms;
	static int32_t cached_milli;
	static int cached_ret = -EAGAIN;
	struct sensor_value val;
	int64_t now = k_uptime_get();
	int ret;

	if (!device_is_ready(dev)) {
		return -ENODEV;
	}

	k_mutex_lock(&lock, K_FOREVER);
	if (cached_ret != 0 || (now - last_ms) >= DIE_TEMP_REFRESH_MS) {
		ret = sensor_sample_fetch(dev);
		if (ret == 0) {
			ret = sensor_channel_get(dev, SENSOR_CHAN_DIE_TEMP, &val);
		}
		if (ret == 0) {
			cached_milli = (int32_t)sensor_value_to_milli(&val);
		}
		cached_ret = ret;
		last_ms = now;
	}
	ret = cached_ret;
	if (ret == 0) {
		temperature->milli_celsius = cached_milli;
		temperature->source = "mcu_die";
	}
	k_mutex_unlock(&lock);

	return ret;
#else
	ARG_UNUSED(temperature);
	return -ENOTSUP;
#endif
}
```
